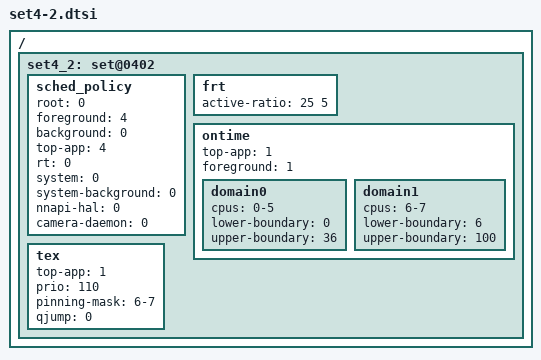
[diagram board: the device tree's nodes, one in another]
/ {
	/* balance mode - app boost */
	set4_2: set@0402{
		sched_policy {
			root = <0>;
			foreground = <4>;
			background = <0>;
			top-app = <4>;
			rt = <0>;
			system = <0>;
			system-background = <0>;
			nnapi-hal = <0>;
			camera-daemon = <0>;
		};

		frt {	   			/* LIT BIG */
			active-ratio 		= < 25   5>;
		};

		/* Ontime Migration */
		ontime {
			top-app		= <1>;
			foreground	= <1>;

			domain0 {
				cpus = "0-5";
				lower-boundary = <0>;
				upper-boundary = <36>;
			};

			domain1 {
				cpus = "6-7";
				lower-boundary = <6>;
				upper-boundary = <100>;
			};
		};

		tex {
			top-app		= <1>;
			prio		= <110>;
			pinning-mask	= "6-7";
			qjump		= <0>;
		};
	};
};
